# RTC_PRM register map
Vendor: Texas Instruments
Peripheral module from a debugger description file (folder TDA2Px).
Registers are 32-bit, access per field, reset 0x0 unless marked. A register's access mark holds for its fields unless they carry their own. Offsets are as the file gives them; lines under a group give offsets from that group; [hi:lo] are bit positions; {n}, {i} and the like mark numbered series; 'fields as' and 'values as' point back to an identical list; <NAME> marks a mode.

## RTC_PRM
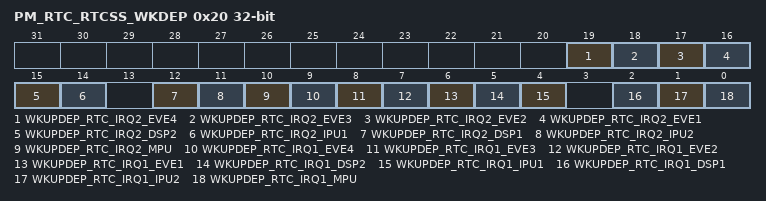
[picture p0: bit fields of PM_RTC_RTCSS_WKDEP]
0x20 PM_RTC_RTCSS_WKDEP — This register controls wakeup dependency based on RTCSS service requests.
  [all] fields
    0=DISABLED (Dependency is disabled); 1=ENABLED (Dependency is enabled)
  [19] WKUPDEP_RTC_IRQ2_EVE4 rw — Wakeup dependency from RTCSS module (timer_swakeup signal) towards EVE4 + L3_MAIN1 + L4PER1 + L4PER2 + L4PER3 domainsEVE4 is not supported in this family of devices.
  [18] WKUPDEP_RTC_IRQ2_EVE3 rw — Wakeup dependency from RTCSS module (timer_swakeup signal) towards EVE3 + L3_MAIN1 + L4PER1 + L4PER2 + L4PER3 domainsEVE3 is not supported in this family of devices.
  [17] WKUPDEP_RTC_IRQ2_EVE2 rw — Wakeup dependency from RTCSS module (timer_swakeup signal) towards EVE2 + L3_MAIN1 + L4PER1 + L4PER2 + L4PER3 domains
  [16] WKUPDEP_RTC_IRQ2_EVE1 rw — Wakeup dependency from RTCSS module (timer_swakeup signal) towards EVE1 + L3_MAIN1 + L4PER1 + L4PER2 + L4PER3 domains
  [15] WKUPDEP_RTC_IRQ2_DSP2 rw — Wakeup dependency from RTCSS module (timer_swakeup signal) towards DSP2 + L3_MAIN1 + L4PER1 + L4PER2 + L4PER3 domains
  [14] WKUPDEP_RTC_IRQ2_IPU1 rw — Wakeup dependency from RTCSS module (timer_swakeup signal) towards IPU1 + L3_MAIN1 + L4PER1 + L4PER2 + L4PER3 domains
  [12] WKUPDEP_RTC_IRQ2_DSP1 rw — Wakeup dependency from RTCSS module (timer_swakeup signal) towards DSP1 + L3_MAIN1 + L4PER1 + L4PER2 + L4PER3 domains
  [11] WKUPDEP_RTC_IRQ2_IPU2 rw — Wakeup dependency from RTCSS module (timer_swakeup signal) towards IPU2 + L3_MAIN1 + L4PER1 + L4PER2 + L4PER3 domains
  [10] WKUPDEP_RTC_IRQ2_MPU rw — Wakeup dependency from RTCSS module (timer_swakeup signal) towards MPU + L3_MAIN1 + L4PER1 + L4PER2 + L4PER3 domains
  [9] WKUPDEP_RTC_IRQ1_EVE4 rw — Wakeup dependency from RTCSS module (alarm_swakeup signal) towards EVE4 + L3_MAIN1 + L4PER1 + L4PER2 + L4PER3 domainsEVE4 is not supported in this family of devices.
  [8] WKUPDEP_RTC_IRQ1_EVE3 rw — Wakeup dependency from RTCSS module (alarm_swakeup signal) towards EVE3 + L3_MAIN1 + L4PER1 + L4PER2 + L4PER3 domainsEVE3 is not supported in this family of devices.
  [7] WKUPDEP_RTC_IRQ1_EVE2 rw — Wakeup dependency from RTCSS module (alarm_swakeup signal) towards EVE2 + L3_MAIN1 + L4PER1 + L4PER2 + L4PER3 domains
  [6] WKUPDEP_RTC_IRQ1_EVE1 rw — Wakeup dependency from RTCSS module ( alarm_swakeup signal) towards EVE1 + L3_MAIN1 + L4PER1 + L4PER2 + L4PER3 domains
  [5] WKUPDEP_RTC_IRQ1_DSP2 rw — Wakeup dependency from RTCSS module (alarm_swakeup signal) towards DSP2 + L3_MAIN1 + L4PER1 + L4PER2 + L4PER3 domains
  [4] WKUPDEP_RTC_IRQ1_IPU1 rw — Wakeup dependency from RTCSS module (alarm_swakeup signal) towards IPU1 + L3_MAIN1 + L4PER1 + L4PER2 + L4PER3 domains
  [2] WKUPDEP_RTC_IRQ1_DSP1 rw — Wakeup dependency from RTCSS module (alarm_swakeup signal) towards DSP1 + L3_MAIN1 + L4PER1 + L4PER2 + L4PER3 domains
  [1] WKUPDEP_RTC_IRQ1_IPU2 rw — Wakeup dependency from RTCSS module ( alarm_swakeup signal) towards IPU2 + L3_MAIN1 + L4PER1 + L4PER2 + L4PER3 domains
  [0] WKUPDEP_RTC_IRQ1_MPU rw — Wakeup dependency from RTCSS module (alarm_swakeup signal) towards MPU + L3_MAIN1 + L4PER1 + L4PER2 + L4PER3 domains
0x24 RM_RTC_RTCSS_CONTEXT reset 0x1 — This register contains dedicated RTCSS context statuses. [warm reset insensitive]
  [0] LOSTCONTEXT_DFF rw — Specify if DFF-based context has been lost due to a previous power transition or other reset source. (set upon assertion of L4PER_RST signal)
    0=MAINTAINED (Context has been maintained); 1=LOST (Context has been lost)
